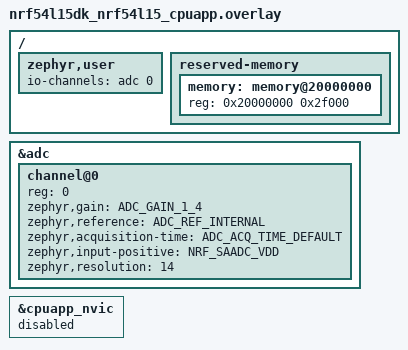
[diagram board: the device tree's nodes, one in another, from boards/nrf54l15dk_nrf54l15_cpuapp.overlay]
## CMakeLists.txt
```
#
# Copyright (c) 2020 Nordic Semiconductor ASA
#
# SPDX-License-Identifier: LicenseRef-Nordic-5-Clause
#
cmake_minimum_required(VERSION 3.20.0)

find_package(Zephyr REQUIRED HINTS $ENV{ZEPHYR_BASE})
project(chat_2)

# NORDIC SDK APP START
target_sources(app PRIVATE
	src/main.c
	src/model_handler.c
	src/chat_cli.c
	src/chat_cli_state.c
	src/chat_cli_neighbor.c
	src/chat_cli_backbone.c
	src/chat_cli_mesh.c
	src/dsdv_routing.c
	src/gradient_routing.c)
target_include_directories(app PRIVATE include)
# NORDIC SDK APP END
```

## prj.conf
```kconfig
#
# Copyright (c) 2020 Nordic Semiconductor ASA
#
# SPDX-License-Identifier: LicenseRef-Nordic-5-Clause
#
CONFIG_NCS_SAMPLES_DEFAULTS=y

# Deferred logging helps improve LPN power consumption
CONFIG_LOG_MODE_DEFERRED=y

# General configuration
CONFIG_NCS_APPLICATION_BOOT_BANNER_STRING="DSDV ROUTING NODE (50 NODES - HIGH BUFFER)"
CONFIG_SYSTEM_WORKQUEUE_STACK_SIZE=4096
CONFIG_FLASH=y
CONFIG_FLASH_MAP=y
CONFIG_NVS=y
CONFIG_SETTINGS=y
CONFIG_NVS_LOOKUP_CACHE=y
CONFIG_SETTINGS_NVS_NAME_CACHE=y
CONFIG_HWINFO=y
CONFIG_DK_LIBRARY=y
CONFIG_PM_PARTITION_SIZE_SETTINGS_STORAGE=0x8000

# Bluetooth configuration
CONFIG_BT=y
CONFIG_BT_DEVICE_NAME="DSDV NODE"
CONFIG_BT_L2CAP_TX_BUF_COUNT=64
CONFIG_BT_OBSERVER=y
CONFIG_BT_PERIPHERAL=y
CONFIG_BT_SETTINGS=y

# Disable unused Bluetooth features
CONFIG_BT_CTLR_LE_ENC=n
CONFIG_BT_PHY_UPDATE=n
CONFIG_BT_CTLR_CHAN_SEL_2=n
CONFIG_BT_CTLR_MIN_USED_CHAN=n
CONFIG_BT_CTLR_PRIVACY=n

# Bluetooth Mesh configuration
CONFIG_BT_MESH=y
# Bật Relay mặc định (để có thể tắt bằng lệnh shell sau)
CONFIG_BT_MESH_RELAY=y
CONFIG_BT_MESH_FRIEND=y 

CONFIG_BT_MESH_SEG_BUFS=128

CONFIG_BT_MESH_RX_SEG_MSG_COUNT=32

CONFIG_BT_MESH_TX_SEG_MSG_COUNT=32

CONFIG_BT_MESH_RX_SEG_MAX=32
CONFIG_BT_MESH_TX_SEG_MAX=32

CONFIG_BT_MESH_MSG_CACHE_SIZE=200

CONFIG_BT_MESH_ADV_BUF_COUNT=60

CONFIG_BT_MESH_PB_GATT=y
CONFIG_BT_MESH_GATT_PROXY=y
CONFIG_BT_MESH_DK_PROV=y

# Log Level
CONFIG_BT_MESH_LOG_LEVEL_WRN=y
CONFIG_BT_MESH_LOG_LEVEL_ERR=y
CONFIG_BT_MESH_LOG_LEVEL_INF=n
CONFIG_BT_MESH_LOG_LEVEL_DBG=n

# Shell module
CONFIG_SHELL=y
CONFIG_SHELL_BACKEND_SERIAL=y
CONFIG_FLASH_SHELL=n
CONFIG_LOG_BACKEND_RTT=n

# CONFIG_BT_CTLR_TX_PWR_MINUS_20=y
CONFIG_BT_CTLR_TX_PWR_0=y

# ADC configuration
CONFIG_ADC=y
CONFIG_ADC_NRFX_SAADC=y

CONFIG_BT_MESH_CRPL=255

CONFIG_LOG_BUFFER_SIZE=40960
```

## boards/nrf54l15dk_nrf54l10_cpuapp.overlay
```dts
/ {
	chosen {
		zephyr,console = &uart30;
		zephyr,shell-uart = &uart30;
		zephyr,uart-mcumgr = &uart30;
		zephyr,bt-mon-uart = &uart30;
		zephyr,bt-c2h-uart = &uart30;
		zephyr,flash-controller = &rram_controller;
		zephyr,flash = &cpuapp_rram;
		zephyr,ieee802154 = &ieee802154;
		zephyr,boot-mode = &boot_mode0;
	};

	aliases {
		mcuboot-button0 = &button0;
		mcuboot-led0 = &led0;
	};
};

&uart30 {
    status="okay"
	current-speed = <115200>;
	pinctrl-0 = <&uart30_default>;
	pinctrl-1 = <&uart30_sleep>;
	pinctrl-names = "default", "sleep";
};
```

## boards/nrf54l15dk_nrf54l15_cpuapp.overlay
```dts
/*
 * Copyright (c) 2025
 * SPDX-License-Identifier: LicenseRef-Nordic-5-Clause
 */

/ {
	zephyr,user {
		io-channels = <&adc 0>;
	};

	reserved-memory {
		#address-cells = <1>;
		#size-cells = <1>;
		ranges;
		memory: memory@20000000 {
			reg = <0x20000000 0x2f000>;
		};
	};
};

&adc {
	#address-cells = <1>;
	#size-cells = <0>;
	status = "okay";
	
	channel@0 {
		reg = <0>;
		zephyr,gain = "ADC_GAIN_1_4";
		zephyr,reference = "ADC_REF_INTERNAL";
		zephyr,acquisition-time = <ADC_ACQ_TIME_DEFAULT>;
		zephyr,input-positive = <NRF_SAADC_VDD>;
		zephyr,resolution = <14>;
	};
};



&cpuapp_nvic {
	status = "disabled";
};
```

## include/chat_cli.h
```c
/*
 * Copyright (c) 2020 Nordic Semiconductor ASA
 *
 * SPDX-License-Identifier: LicenseRef-Nordic-5-Clause
 */

/**
 * @file chat_cli.h
 * @defgroup bt_mesh_chat_cli Bluetooth Mesh Chat Client Model API
 * @{
 * @brief API for the Bluetooth Mesh Chat Client model with DSDV routing
 * 
 * This model implements:
 * - DSDV (Destination-Sequenced Distance-Vector) proactive routing protocol
 * - Network metrics collection (hop count, RSSI)
 * - Automatic expired route filtering (timeout-based)
 * - Remote structure querying
 */

#ifndef BT_MESH_CHAT_CLI_H__
#define BT_MESH_CHAT_CLI_H__

#include <zephyr/bluetooth/mesh.h>
#include <bluetooth/mesh/model_types.h>

#ifdef __cplusplus
extern "C" {
#endif

/* ============================================================================
 * MODEL IDENTIFICATION
 * ============================================================================ */

/** Company ID of the Bluetooth Mesh Chat Client model. */
#define BT_MESH_CHAT_CLI_VENDOR_COMPANY_ID    CONFIG_BT_COMPANY_ID_NORDIC

/** Model ID of the Bluetooth Mesh Chat Client model. */
#define BT_MESH_CHAT_CLI_VENDOR_MODEL_ID      0x000A

/* ============================================================================
 * OPCODES - Mesh message operation codes
 * ============================================================================ */

/** Opcode: Metrics acknowledgment packet */
#define BT_MESH_CHAT_CLI_OP_METRICS_ACK BT_MESH_MODEL_OP_3(0x0F, \
                                       BT_MESH_CHAT_CLI_VENDOR_COMPANY_ID)
/** Opcode: DSDV HELLO packet (neighbor discovery + RSSI) */
#define BT_MESH_CHAT_CLI_OP_DSDV_HELLO BT_MESH_MODEL_OP_3(0x12, \
									   BT_MESH_CHAT_CLI_VENDOR_COMPANY_ID)

/** Opcode: DSDV UPDATE packet (routing table exchange) */
#define BT_MESH_CHAT_CLI_OP_DSDV_UPDATE BT_MESH_MODEL_OP_3(0x13, \
									   BT_MESH_CHAT_CLI_VENDOR_COMPANY_ID)

/** Opcode: DSDV DATA packet (end-to-end data with metrics) */
#define BT_MESH_CHAT_CLI_OP_DSDV_DATA BT_MESH_MODEL_OP_3(0x14, \
									   BT_MESH_CHAT_CLI_VENDOR_COMPANY_ID)

/** Opcode: LED toggle packet (remote LED control) */
#define BT_MESH_CHAT_CLI_OP_LED_TOGGLE BT_MESH_MODEL_OP_3(0x15, \
									   BT_MESH_CHAT_CLI_VENDOR_COMPANY_ID)

/* ============================================================================
 * NODE ROLE ENUM — MCDS Backbone Selection
 * ============================================================================ */

/** Node role in the MCDS backbone hierarchy */
typedef enum {
    NODE_ROLE_UNKNOWN  = 0,  /**< Role not yet determined */
    NODE_ROLE_BACKBONE = 1,  /**< Relay ON, full routing, higher TTL */
    NODE_ROLE_LEAF     = 2,  /**< Relay OFF, local only, lower TTL */
} node_role_t;

/* ============================================================================
 * MESSAGE LENGTH CONSTANTS
 * ============================================================================ */
									   
#define BT_MESH_CHAT_CLI_MSG_LEN_DSDV_HELLO sizeof(struct dsdv_hello) /**< HELLO packet size */
#define BT_MESH_CHAT_CLI_MSG_LEN_DSDV_UPDATE_MIN 8           /**< Minimum UPDATE packet size */
#define BT_MESH_CHAT_CLI_MSG_LEN_METRICS_ACK 8               /**< Metrics ACK packet size */
#define BT_MESH_CHAT_CLI_MSG_LEN_DSDV_DATA_MAX 128           /**< Maximum DATA packet size */
#define BT_MESH_CHAT_CLI_MSG_LEN_LED_TOGGLE 8                /**< LED toggle packet size */

/* ============================================================================
 * DATA STRUCTURES - Packet formats and routing table entries
 * ============================================================================ */

/** Maximum number of neighbors to include in metrics packet */
#define MAX_NEIGHBORS_IN_METRICS 8

/**
 * @brief Network metrics packet structure
 * 
 * Contains basic network performance metrics from a node:
 * - Link quality (RSSI to target)
 * - Routing info (hop count, TTL)
 */
struct bt_mesh_network_metrics
{
	uint16_t src_addr;      /**< Source node address */
	uint16_t about_addr;    /**< Target node address (for directed metrics) */
	uint32_t timestamp;     /**< Metric collection timestamp (ms) */
	int8_t rssi_dbm;        /**< RSSI to about_addr in dBm */
	uint8_t initial_ttl;    /**< TTL used for packet transmission */
	uint8_t hop_count;      /**< Number of hops from source */
	uint8_t request_ack;    /**< 1 = request acknowledgment, 0 = no ACK needed */
	uint8_t _padding;       /**< Padding for alignment */
}__packed;

/**
 * @brief Metrics acknowledgment packet
 * 
 * Sent by destination to confirm metrics packet delivery.
 * Enables RTT (Round Trip Time) calculation.
 */
struct bt_mesh_metrics_ack{
	uint16_t src_addr;           /**< Original sender address */
	uint32_t original_timestamp; /**< Echo of original timestamp for RTT calculation */
	uint16_t padding;            /**< Padding to reach 8 bytes */
} __packed;

/**
 * @brief DSDV routing table entry
 * 
 * Stores routing information for one destination in the network.
 * Updated when receiving HELLO or UPDATE packets.
 */
struct dsdv_route_entry {
	uint16_t dest;               /**< Destination node address */
	uint16_t next_hop;           /**< Next hop node address to reach dest */
	uint8_t hop_count;           /**< Number of hops to destination (0xFF = invalidation) */
	uint32_t seq_num;            /**< Sequence number from destination (freshness / odd=invalid) */
	uint32_t last_update_time;   /**< Last successful update time (ms) */
	uint8_t changed;             
	uint8_t _pad;                /**< Padding for alignment */
}__packed;

/**
 * @brief DSDV HELLO packet structure
 * 
 * Broadcast periodically for neighbor discovery.
 * Receivers create 1-hop routes, measure RSSI, and learn neighbor degree/role
 * for MCDS backbone selection.
 */
struct dsdv_hello {
    uint16_t src;       /**< Source node address */
    uint32_t seq_num;   /**< Source's sequence number (even numbers only) */
    uint8_t  my_degree; /**< Number of active neighbors (for backbone election) */
    uint8_t  my_role;   /**< Current node role: NODE_ROLE_UNKNOWN/BACKBONE/LEAF */
    uint8_t  my_leaf_type;      /**< 0=none/backbone, 1=leaf with backbone neighbor, 2=leaf gradient-only */
    uint8_t  my_gradient_level; /**< 0 for type-1 leaf, >0 for gradient leaf, 0xFF unknown */
} __packed;

/**
 * @brief DSDV UPDATE packet header
 * 
 * Followed by num_entries route entries.
 * Shares routing table with neighbors for multi-hop routing.
 */
struct dsdv_update_header {
	uint16_t src;         /**< Source node address */
	uint8_t num_entries;  /**< Number of route entries following this header */
	uint8_t flags;        /**< Reserved flags */
} __packed;

/**
 * @brief DSDV UPDATE route entry payload
 * 
 * Sent in UPDATE packets. Does NOT include next_hop because:
 * - Receiver will set next_hop = sender_address
 * - Including next_hop would cause routing errors (transitive next_hop)
 */
struct dsdv_update_entry {
	uint16_t dest;        /**< Destination node address */
	uint8_t hop_count;    /**< Number of hops from sender to dest */
	uint32_t seq_num;     /**< Sequence number from destination */
	uint8_t padding;      /**< Padding for alignment */
} __packed;

/** Maximum number of nodes in path vector for DATA packets */
#define MAX_PATH_NODES 8

/**
 * @brief DSDV DATA packet structure
 * 
 * End-to-end data delivery with embedded metrics and path tracking.
 * Supports relay metrics collection for network analysis.
 */
struct dsdv_data_packet {
	uint16_t src;
	uint16_t dest;
	uint32_t seq_num;
	uint8_t hop_count;
	uint8_t path_len;
	uint16_t path_nodes[MAX_PATH_NODES];
	
	// Sequential mode: Only source metrics in main packet
	struct bt_mesh_network_metrics metrics;
	uint8_t collect_relay_metrics;  // Flag: 1 = relays send metrics separately
} __packed;

/**
 * @brief LED toggle message structure
 * 
 * Remote LED control message sent through DSDV routing.
 * Contains source address, destination address, and sequence number
 * for duplicate detection and routing.
 */
struct led_toggle_message {
	uint16_t src;        /**< Source node address */
	uint16_t dest;       /**< Destination node address */
	uint32_t seq_num;    /**< Sequence number for duplicate detection */
} __packed;

/* Forward declaration of the Bluetooth Mesh Chat Client model context. */
struct bt_mesh_chat_cli;

/* .. include_startingpoint_chat_cli_rst_2 */
/** @def BT_MESH_MODEL_CHAT_CLI
 *
 * @brief Bluetooth Mesh Chat Client model composition data entry.
 *
 * @param[in] _chat Pointer to a @ref bt_mesh_chat_cli instance.
 */
#define BT_MESH_MODEL_CHAT_CLI(_chat)                                          \
		BT_MESH_MODEL_VND_CB(BT_MESH_CHAT_CLI_VENDOR_COMPANY_ID,       \
			BT_MESH_CHAT_CLI_VENDOR_MODEL_ID,                      \
			_bt_mesh_chat_cli_op, &(_chat)->pub,                   \
			BT_MESH_MODEL_USER_DATA(struct bt_mesh_chat_cli,       \
						_chat),                        \
			&_bt_mesh_chat_cli_cb)
/* .. include_endpoint_chat_cli_rst_2 */

/** Bluetooth Mesh Chat Client model handlers. */
struct bt_mesh_chat_cli_handlers {
	/** @brief Called after the node has been provisioned, or after all
	 * mesh data has been loaded from persistent storage.
	 *
	 * @param[in] cli Chat Client instance that has been started.
	 */
	void (*const start)(struct bt_mesh_chat_cli *chat);

	/** @brief Handler for a network metrics message.
	 *
	 * @param[in] cli Chat client instance that received the message.
	 * @param[in] ctx Context of the incoming message.
	 * @param[in] metrics Pointer to the network metrics data.
	 */
	void (*const network_metrics)(struct bt_mesh_chat_cli *chat,
				       struct bt_mesh_msg_ctx *ctx,
				       const struct bt_mesh_network_metrics *metrics);
	
	/** @brief Handler for metrics ACK message.
	 * @param[in] chat Chat client instance.
	 * @param[in] ctx Context of the incoming message.
	 * @param[in] ack Metrics ACK data.
 */
	void (*const metrics_ack)(struct bt_mesh_chat_cli *chat,
				  struct bt_mesh_msg_ctx *ctx,
				  const struct bt_mesh_metrics_ack *ack);
};

/* .. include_startingpoint_chat_cli_rst_3 */
/**
 * Bluetooth Mesh Chat Client model context.
 */
struct bt_mesh_chat_cli {
	/** Access model pointer. */
	const struct bt_mesh_model *model;
	/** Publish parameters. */
	struct bt_mesh_model_pub pub;
	/** Publication message. */
	struct net_buf_simple pub_msg;
	/** Publication message buffer. */
	uint8_t buf[BT_MESH_MODEL_BUF_LEN(BT_MESH_CHAT_CLI_OP_DSDV_UPDATE,
					  BT_MESH_CHAT_CLI_MSG_LEN_DSDV_DATA_MAX)];
	/** Handler function structure. */
	const struct bt_mesh_chat_cli_handlers *handlers;
};
/* .. include_endpoint_chat_cli_rst_3 */

/** @brief Send network metrics to specified destination.
 *
 * @param[in] chat Chat Client model instance to send the message.
 * @param[in] addr Address of the destination node.
 * @param[in] metrics Pointer to network metrics data to send.
 *
 * @retval 0 Successfully sent the message.
 * @retval -EINVAL The model is not bound to an application key.
 * @retval -EAGAIN The device has not been provisioned.
 */
/** @brief set target node for metrics collection.
 *
 * @param[in] target_addr Address of target node for metrics.
 */
void bt_mesh_chat_cli_set_metrics_target(uint16_t target_addr);

/** @brief Get neighbor RSSI statistics.
 *
 * Returns the number of neighbors with RSSI data.
 * Fills the provided arrays with neighbor addresses and RSSI values.
 *
 * @param[out] addrs Array to store neighbor addresses (must have space for 16).
 * @param[out] rssi Array to store RSSI values (must have space for 16).
 * @param[in] max_count Maximum number of entries to return.
 *
 * @return Number of neighbors returned.
 */
int bt_mesh_chat_cli_get_neighbor_rssi(uint16_t *addrs, int8_t *rssi, int max_count);

/** @brief Send network metrics immediately via DSDV.
 *
 * Attempts to find a DSDV route and unicast a metrics packet to @p addr.
 * If no route is found, returns an error and does not publish/broadcast.
 *
 * @param[in] chat Chat Client model instance.
 * @param[in] addr Destination unicast address.
 *
 * @retval 0 on success.
 * @retval -EINVAL Invalid args or addr.
 * @retval -ENOENT No route to destination.
 */
int bt_mesh_chat_cli_metrics_send(struct bt_mesh_chat_cli *chat, uint16_t addr);


/**
 * @brief Request network structure from a node
 *
 * Sends a structure request to the specified node. The target node will
 * reply with its complete DSDV routing table, showing all known nodes,
 * their next_hop addresses, hop counts, and RSSI values.
 *
 * @param[in] chat Chat Client model instance.
 * @param[in] dest Destination unicast address to request structure from.
 *
 * @retval 0 on success.
 * @retval -EINVAL Invalid arguments or destination address.
 * @retval -ENOENT No route to destination.
 */
int bt_mesh_chat_cli_structure_request(struct bt_mesh_chat_cli *chat, uint16_t dest);

/**
 * @brief Send LED toggle command to a remote node
 *
 * Sends an LED toggle message to the specified destination node through
 * DSDV routing. The target node will blink its LED1 three times upon
 * receiving the message.
 *
 * @param[in] chat Chat Client model instance.
 * @param[in] dest Destination unicast address to send LED toggle command.
 *
 * @retval 0 on success.
 * @retval -EINVAL Invalid arguments or destination address.
 * @retval -ENOENT No route to destination.
 */
int bt_mesh_chat_cli_led_toggle_send(struct bt_mesh_chat_cli *chat, uint16_t dest);

/** @brief Get the current node role (BACKBONE/LEAF/UNKNOWN).
 * @return Current node_role_t value.
 */
node_role_t bt_mesh_chat_cli_get_node_role(void);

/** @brief Get list of known backbone node addresses.
 * @param[out] backbone_addrs Array to fill with backbone addresses.
 * @param[in] max_count Maximum entries to return.
 * @return Number of backbone nodes found.
 */
int bt_mesh_chat_cli_get_backbone_info(uint16_t *backbone_addrs, int max_count);

/** @brief Get the current node's backbone score.
 * @return Centrality score used in backbone election.
 */
uint16_t bt_mesh_chat_cli_get_backbone_score(void);

/** @cond INTERNAL_HIDDEN */
extern const struct bt_mesh_model_op _bt_mesh_chat_cli_op[];
extern const struct bt_mesh_model_cb _bt_mesh_chat_cli_cb;
/** @endcond */

#ifdef __cplusplus
}
#endif

#endif /* BT_MESH_CHAT_CLI_H__ */

/** @} */
```

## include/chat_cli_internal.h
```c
/*
 * Shared state and internal API for Bluetooth Mesh Chat Client (DSDV + backbone + hybrid).
 */

#ifndef CHAT_CLI_INTERNAL_H__
#define CHAT_CLI_INTERNAL_H__

#include <stddef.h>
#include <stdint.h>

#include <zephyr/bluetooth/mesh.h>
#include <zephyr/kernel.h>

#include "chat_cli.h"
#include "dsdv_routing.h"
#include "gradient_routing.h"

#ifdef __cplusplus
extern "C" {
#endif

#define MAX_UPDATE_ENTRIES 12
#define MAX_RSSI_NEIGHBORS 32
#define NEIGHBOR_RSSI_VALID_WINDOW_MS 90000
#define MAX_ROUTE_HISTORY 5
#define UPDATE_MIN_INTERVAL_MS 3000

#define TTL_HELLO 1
#define TTL_DEFAULT_MAX 10

#define BACKBONE_RSSI_THRESHOLD (-70)
#define BACKBONE_RSSI_REJECT (-80)
#define BACKBONE_MIN_DEGREE 3
#define BACKBONE_PROMOTE_MIN_DEGREE 2
#define BACKBONE_PROMOTE_RSSI (-80)
#define BACKBONE_EVAL_INTERVAL_MS 30000
#define BACKBONE_INITIAL_DELAY_MS 15000
#define BACKBONE_PDR_REJECT 50
#define BACKBONE_PDR_WINDOW_MS 60000
#define BACKBONE_EXPECTED_HELLO_MS 12000

typedef enum {
	CHAT_CLI_MSG_HELLO,
	CHAT_CLI_MSG_UPDATE,
	CHAT_CLI_MSG_UNICAST_DATA,
	CHAT_CLI_MSG_BROADCAST_APP,
} chat_cli_msg_type_t;

typedef struct {
	uint16_t addr;
	int8_t rssi;
	uint32_t last_update;
} chat_cli_neighbor_rssi_t;

typedef struct {
	uint16_t addr;
	uint8_t degree;
	uint8_t role;
	uint8_t leaf_type;
	uint8_t gradient_level;
	int8_t avg_rssi;
	uint32_t last_seen;
	uint16_t hello_rx_count;
	uint32_t pdr_window_start;
} chat_cli_backbone_peer_t;

extern struct bt_mesh_chat_cli *g_chat_cli_instance;
extern struct k_work_delayable dsdv_hello_work;
extern struct k_work_delayable dsdv_update_work;
extern struct k_work_delayable print_routes_work;
extern struct k_work_delayable backbone_selection_work;

extern chat_cli_neighbor_rssi_t neighbor_rssi[MAX_RSSI_NEIGHBORS];
extern chat_cli_backbone_peer_t neighbor_backbone_info[MAX_RSSI_NEIGHBORS];

extern node_role_t g_my_role;
extern uint16_t g_my_degree;
extern uint16_t g_my_backbone_score;
extern struct gradient_state g_gradient_state;

extern uint16_t current_target_node;
extern uint32_t g_dsdv_my_seq;
extern uint32_t last_update_sent_time;

typedef struct {
	uint32_t packets_sent;
	uint32_t packets_acked;
	uint32_t window_start;
} chat_cli_delivery_stats_t;

extern chat_cli_delivery_stats_t delivery_stats;

/* neighbor_rssi.c */
void chat_cli_update_neighbor_rssi(uint16_t addr, int8_t rssi);
int8_t chat_cli_get_neighbor_rssi(uint16_t addr);
int8_t chat_cli_dsdv_rssi_cb(uint16_t addr);

/* backbone.c */
void chat_cli_backbone_evaluate(void);
void chat_cli_backbone_selection_handler(struct k_work *work);
void chat_cli_refresh_leaf_routing_mode(void);
uint16_t chat_cli_select_hybrid_next_hop(uint16_t dest);

/* mesh_handlers.c */
uint8_t chat_cli_calc_ttl(chat_cli_msg_type_t type, uint16_t dst);
void chat_cli_dsdv_send_hello(struct k_work *work);
void chat_cli_dsdv_send_update(struct k_work *work);
void chat_cli_print_routes_handler(struct k_work *work);
void chat_cli_print_routing_table(void);
void chat_cli_check_delivery_window(void);

int chat_cli_handle_dsdv_hello(const struct bt_mesh_model *model, struct bt_mesh_msg_ctx *ctx,
			       struct net_buf_simple *buf);
int chat_cli_handle_dsdv_update(const struct bt_mesh_model *model, struct bt_mesh_msg_ctx *ctx,
				struct net_buf_simple *buf);
int chat_cli_handle_dsdv_data(const struct bt_mesh_model *model, struct bt_mesh_msg_ctx *ctx,
			      struct net_buf_simple *buf);
int chat_cli_handle_led_toggle(const struct bt_mesh_model *model, struct bt_mesh_msg_ctx *ctx,
			       struct net_buf_simple *buf);
int chat_cli_handle_metrics_ack(const struct bt_mesh_model *model, struct bt_mesh_msg_ctx *ctx,
				struct net_buf_simple *buf);

void chat_cli_collect_current_metrics(struct bt_mesh_chat_cli *chat,
				      struct bt_mesh_network_metrics *metrics);
void chat_cli_send_metrics_ack(struct bt_mesh_chat_cli *chat, struct bt_mesh_msg_ctx *ctx,
			       const struct bt_mesh_network_metrics *original_metrics);

#ifdef __cplusplus
}
#endif

#endif /* CHAT_CLI_INTERNAL_H__ */
```

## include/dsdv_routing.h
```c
/*
 * DSDV (Destination-Sequenced Distance-Vector) routing core for mesh chat.
 */

#ifndef DSDV_ROUTING_H__
#define DSDV_ROUTING_H__

#include <stdbool.h>
#include <stdint.h>

#include "chat_cli.h"

#ifdef __cplusplus
extern "C" {
#endif

#define DSDV_ROUTE_TABLE_SIZE 64
#define DSDV_DUP_CACHE_SIZE 100

#define DSDV_NEIGHBOR_TIMEOUT_MS 45000
#define DSDV_ROUTE_TIMEOUT_MS    120000
#define ROUTE_SETTLE_TIME_MS     10000

extern struct dsdv_route_entry g_dsdv_routes[DSDV_ROUTE_TABLE_SIZE];

extern bool dsdv_route_changed;
extern bool dsdv_my_info_changed;

typedef int8_t (*dsdv_get_neighbor_rssi_fn)(uint16_t addr);

struct dsdv_route_entry *dsdv_find_route(uint16_t dest);

void dsdv_cleanup_expired_routes(void);

bool dsdv_upsert(uint16_t dest, uint16_t next_hop, uint8_t hop_count, uint32_t seq_num,
		 dsdv_get_neighbor_rssi_fn get_rssi);

bool dsdv_seen_duplicate(uint16_t src, uint32_t seq);

#ifdef __cplusplus
}
#endif

#endif /* DSDV_ROUTING_H__ */
```

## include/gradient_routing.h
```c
#ifndef GRADIENT_ROUTING_H__
#define GRADIENT_ROUTING_H__

#include <stddef.h>
#include <stdint.h>

#include "chat_cli.h"

#ifdef __cplusplus
extern "C" {
#endif

#define LEAF_TYPE_NONE 0
#define LEAF_TYPE_BACKBONE_NEIGHBOR 1
#define LEAF_TYPE_GRADIENT 2
#define GRADIENT_LEVEL_UNKNOWN 0xFF

struct gradient_neighbor_info {
    uint16_t addr;
    uint8_t role;
    uint8_t leaf_type;
    uint8_t gradient_level;
    int8_t rssi;
    uint32_t last_seen;
};

struct gradient_state {
    uint8_t leaf_type;
    uint8_t gradient_level;
    uint16_t attached_backbone;
    uint16_t gradient_next_hop;
};

void gradient_compute_state(node_role_t my_role,
                            const struct gradient_neighbor_info *neighbors,
                            size_t neighbor_count,
                            uint32_t now_ms,
                            uint32_t valid_window_ms,
                            struct gradient_state *state);

uint16_t gradient_pick_next_hop(uint16_t dsdv_next_hop,
                                node_role_t my_role,
                                const struct gradient_state *state);

#ifdef __cplusplus
}
#endif

#endif /* GRADIENT_ROUTING_H__ */
```

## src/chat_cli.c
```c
/*
 * Copyright (c) 2019 Nordic Semiconductor ASA
 *
 * SPDX-License-Identifier: LicenseRef-Nordic-5-Clause
 */

/**
 * @file chat_cli.c
 * @brief Bluetooth Mesh Chat Client model: registration, lifecycle, opcode table.
 */

#include <zephyr/bluetooth/mesh.h>

#include "chat_cli.h"
#include "chat_cli_internal.h"

#include <zephyr/kernel.h>
#include <zephyr/random/random.h>

#ifdef CONFIG_BT_SETTINGS
#include <zephyr/settings/settings.h>
#endif

const struct bt_mesh_model_op _bt_mesh_chat_cli_op[] = {
	{ BT_MESH_CHAT_CLI_OP_METRICS_ACK, BT_MESH_LEN_EXACT(BT_MESH_CHAT_CLI_MSG_LEN_METRICS_ACK),
	  chat_cli_handle_metrics_ack },
	{ BT_MESH_CHAT_CLI_OP_DSDV_HELLO, BT_MESH_LEN_EXACT(sizeof(struct dsdv_hello)),
	  chat_cli_handle_dsdv_hello },
	{ BT_MESH_CHAT_CLI_OP_DSDV_UPDATE, BT_MESH_LEN_MIN(BT_MESH_CHAT_CLI_MSG_LEN_DSDV_UPDATE_MIN),
	  chat_cli_handle_dsdv_update },
	{ BT_MESH_CHAT_CLI_OP_DSDV_DATA, BT_MESH_LEN_MIN(sizeof(struct dsdv_data_packet)),
	  chat_cli_handle_dsdv_data },
	{ BT_MESH_CHAT_CLI_OP_LED_TOGGLE, BT_MESH_LEN_EXACT(BT_MESH_CHAT_CLI_MSG_LEN_LED_TOGGLE),
	  chat_cli_handle_led_toggle },
	BT_MESH_MODEL_OP_END,
};

#ifdef CONFIG_BT_SETTINGS
static int bt_mesh_chat_cli_settings_set(const struct bt_mesh_model *model, const char *name,
					   size_t len_rd, settings_read_cb read_cb, void *cb_arg)
{
	if (name) {
		return -ENOENT;
	}
	return 0;
}
#endif

static int bt_mesh_chat_cli_init(const struct bt_mesh_model *model)
{
	struct bt_mesh_chat_cli *chat = model->rt->user_data;

	chat->model = model;
	net_buf_simple_init_with_data(&chat->pub_msg, chat->buf, sizeof(chat->buf));
	chat->pub.msg = &chat->pub_msg;
	chat->pub.update = NULL;
	k_work_init_delayable(&dsdv_hello_work, chat_cli_dsdv_send_hello);
	k_work_init_delayable(&dsdv_update_work, chat_cli_dsdv_send_update);
	k_work_init_delayable(&print_routes_work, chat_cli_print_routes_handler);
	k_work_init_delayable(&backbone_selection_work, chat_cli_backbone_selection_handler);
	return 0;
}

static int bt_mesh_chat_cli_start(const struct bt_mesh_model *model)
{
	struct bt_mesh_chat_cli *chat = model->rt->user_data;

	if (chat->handlers->start) {
		chat->handlers->start(chat);
	}
	g_chat_cli_instance = chat;

	k_work_schedule(&dsdv_hello_work, K_MSEC(2000 + (sys_rand32_get() % 5000)));
	k_work_schedule(&dsdv_update_work, K_MSEC(3000 + (sys_rand32_get() % 2000)));
	k_work_schedule(&print_routes_work, K_MSEC(10000));
	k_work_schedule(&backbone_selection_work,
			K_MSEC(BACKBONE_INITIAL_DELAY_MS + (sys_rand32_get() % 5000)));
	return 0;
}

const struct bt_mesh_model_cb _bt_mesh_chat_cli_cb = {
	.init = bt_mesh_chat_cli_init,
	.start = bt_mesh_chat_cli_start,
#ifdef CONFIG_BT_SETTINGS
	.settings_set = bt_mesh_chat_cli_settings_set,
#endif
};

void bt_mesh_chat_cli_set_metrics_target(uint16_t target_addr)
{
	current_target_node = target_addr;
}
```

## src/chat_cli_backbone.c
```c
/*
 * MCDS backbone election + hybrid gradient next-hop.
 */

#include "chat_cli_internal.h"

#include <zephyr/logging/log.h>
#include <zephyr/random/random.h>

LOG_MODULE_DECLARE(chat);

static int8_t calc_avg_neighbor_rssi(void)
{
	int32_t sum = 0;
	int count = 0;
	uint32_t now = k_uptime_get_32();

	for (int i = 0; i < MAX_RSSI_NEIGHBORS; i++) {
		if (neighbor_rssi[i].addr != 0 &&
		    (now - neighbor_rssi[i].last_update) < NEIGHBOR_RSSI_VALID_WINDOW_MS) {
			sum += neighbor_rssi[i].rssi;
			count++;
		}
	}
	return (count > 0) ? (int8_t)(sum / count) : -127;
}

static uint8_t calc_avg_neighbor_pdr(void)
{
	uint32_t now = k_uptime_get_32();
	uint32_t total_pdr = 0;
	int count = 0;

	for (int i = 0; i < MAX_RSSI_NEIGHBORS; i++) {
		if (neighbor_backbone_info[i].addr == 0) {
			continue;
		}
		if ((now - neighbor_backbone_info[i].last_seen) > NEIGHBOR_RSSI_VALID_WINDOW_MS) {
			continue;
		}

		uint32_t window_ms = now - neighbor_backbone_info[i].pdr_window_start;
		if (window_ms < 5000) {
			total_pdr += 100;
			count++;
			continue;
		}

		uint16_t expected = (uint16_t)(window_ms / BACKBONE_EXPECTED_HELLO_MS);
		if (expected == 0) {
			expected = 1;
		}

		uint16_t pdr = (neighbor_backbone_info[i].hello_rx_count * 100) / expected;
		if (pdr > 100) {
			pdr = 100;
		}

		total_pdr += pdr;
		count++;
	}

	return (count > 0) ? (uint8_t)(total_pdr / count) : 0;
}

static uint16_t calc_backbone_score_for(uint8_t degree, int8_t avg_rssi, uint8_t pdr)
{
	int16_t rssi_score = (int16_t)(avg_rssi + 100);
	if (rssi_score < 0) {
		rssi_score = 0;
	}
	if (rssi_score > 70) {
		rssi_score = 70;
	}
	uint16_t pdr_bonus = (uint16_t)(pdr * 30 / 100);
	return (uint16_t)(degree * 100) + (uint16_t)rssi_score + pdr_bonus;
}

void chat_cli_backbone_evaluate(void)
{
	if (!g_chat_cli_instance || !g_chat_cli_instance->model) {
		return;
	}

	uint16_t my_addr = bt_mesh_model_elem(g_chat_cli_instance->model)->rt->addr;
	uint32_t now = k_uptime_get_32();
	node_role_t old_role = g_my_role;

	uint16_t active_neighbors = 0;
	for (int i = 0; i < MAX_RSSI_NEIGHBORS; i++) {
		if (neighbor_rssi[i].addr != 0 &&
		    (now - neighbor_rssi[i].last_update) < NEIGHBOR_RSSI_VALID_WINDOW_MS) {
			active_neighbors++;
		}
	}
	g_my_degree = active_neighbors;

	int8_t my_avg_rssi = calc_avg_neighbor_rssi();
	uint8_t my_avg_pdr = calc_avg_neighbor_pdr();

	if (g_my_degree < 2) {
		g_my_role = NODE_ROLE_LEAF;
		g_my_backbone_score = 0;
		LOG_INF("BACKBONE: LEAF (degree %u < 2, edge node)", g_my_degree);
		goto apply_role;
	}

	if (my_avg_rssi < BACKBONE_RSSI_REJECT) {
		g_my_role = NODE_ROLE_LEAF;
		g_my_backbone_score = 0;
		LOG_INF("BACKBONE: LEAF (avg RSSI %d < %d, weak signal)", my_avg_rssi,
			BACKBONE_RSSI_REJECT);
		goto apply_role;
	}

	if (my_avg_pdr < BACKBONE_PDR_REJECT) {
		g_my_role = NODE_ROLE_LEAF;
		g_my_backbone_score = 0;
		LOG_INF("BACKBONE: LEAF (avg PDR %u%% < %d%%, unreliable)", my_avg_pdr,
			BACKBONE_PDR_REJECT);
		goto apply_role;
	}

	uint16_t my_score = calc_backbone_score_for((uint8_t)g_my_degree, my_avg_rssi, my_avg_pdr);
	g_my_backbone_score = my_score;

	bool i_am_highest = true;

	for (int i = 0; i < MAX_RSSI_NEIGHBORS; i++) {
		if (neighbor_backbone_info[i].addr == 0) {
			continue;
		}
		if ((now - neighbor_backbone_info[i].last_seen) > NEIGHBOR_RSSI_VALID_WINDOW_MS) {
			continue;
		}

		uint8_t nb_pdr = 100;
		{
			uint32_t w = now - neighbor_backbone_info[i].pdr_window_start;
			if (w > 5000) {
				uint16_t exp = (uint16_t)(w / BACKBONE_EXPECTED_HELLO_MS);
				if (exp == 0) {
					exp = 1;
				}
				nb_pdr = (uint8_t)((neighbor_backbone_info[i].hello_rx_count * 100) / exp);
				if (nb_pdr > 100) {
					nb_pdr = 100;
				}
			}
		}
		uint16_t neighbor_score = calc_backbone_score_for(neighbor_backbone_info[i].degree,
								  neighbor_backbone_info[i].avg_rssi,
								  nb_pdr);

		if (neighbor_score > my_score) {
			i_am_highest = false;
			break;
		} else if (neighbor_score == my_score) {
			if (neighbor_backbone_info[i].addr < my_addr) {
				i_am_highest = false;
				break;
			}
		}
	}

	if (i_am_highest && g_my_degree >= BACKBONE_MIN_DEGREE && my_avg_rssi >= BACKBONE_RSSI_THRESHOLD &&
	    my_avg_pdr >= BACKBONE_PDR_REJECT) {
		g_my_role = NODE_ROLE_BACKBONE;
	} else {
		g_my_role = NODE_ROLE_LEAF;
	}

	if (g_my_role == NODE_ROLE_LEAF) {
		bool has_backbone_neighbor = false;

		for (int i = 0; i < MAX_RSSI_NEIGHBORS; i++) {
			if (neighbor_backbone_info[i].addr == 0) {
				continue;
			}
			if ((now - neighbor_backbone_info[i].last_seen) > NEIGHBOR_RSSI_VALID_WINDOW_MS) {
				continue;
			}

			if (neighbor_backbone_info[i].role == NODE_ROLE_BACKBONE) {
				has_backbone_neighbor = true;
				break;
			}
		}

		if (!has_backbone_neighbor && g_my_degree >= BACKBONE_PROMOTE_MIN_DEGREE &&
		    my_avg_rssi >= BACKBONE_PROMOTE_RSSI && my_avg_pdr >= BACKBONE_PDR_REJECT) {
			g_my_role = NODE_ROLE_BACKBONE;
			LOG_INF("BACKBONE: Forced BACKBONE (isolated, promote thresholds met)");
		}
	}

	LOG_INF("BACKBONE: Role=%s Score=%u Degree=%u AvgRSSI=%d",
		(g_my_role == NODE_ROLE_BACKBONE) ? "BACKBONE" : "LEAF", g_my_backbone_score, g_my_degree,
		my_avg_rssi);

apply_role:
	if (g_my_role != old_role) {
#if defined(CONFIG_BT_MESH_CFG_SRV)
		extern void bt_mesh_cfg_srv_relay_set(uint8_t new_relay, uint8_t new_transmit);
		if (g_my_role == NODE_ROLE_BACKBONE) {
			bt_mesh_cfg_srv_relay_set(BT_MESH_RELAY_ENABLED, BT_MESH_TRANSMIT(2, 20));
			LOG_INF("BACKBONE: Relay ENABLED (Backbone node)");
		} else {
			bt_mesh_cfg_srv_relay_set(BT_MESH_RELAY_DISABLED, BT_MESH_TRANSMIT(2, 20));
			LOG_INF("BACKBONE: Relay DISABLED (Leaf node)");
		}
#endif
	}
	chat_cli_refresh_leaf_routing_mode();
}

void chat_cli_refresh_leaf_routing_mode(void)
{
	uint32_t now = k_uptime_get_32();
	struct gradient_neighbor_info grad_neighbors[MAX_RSSI_NEIGHBORS];
	size_t grad_count = 0;

	for (int i = 0; i < MAX_RSSI_NEIGHBORS; i++) {
		if (neighbor_backbone_info[i].addr == 0) {
			continue;
		}
		grad_neighbors[grad_count].addr = neighbor_backbone_info[i].addr;
		grad_neighbors[grad_count].role = neighbor_backbone_info[i].role;
		grad_neighbors[grad_count].leaf_type = neighbor_backbone_info[i].leaf_type;
		grad_neighbors[grad_count].gradient_level = neighbor_backbone_info[i].gradient_level;
		grad_neighbors[grad_count].rssi = chat_cli_get_neighbor_rssi(neighbor_backbone_info[i].addr);
		grad_neighbors[grad_count].last_seen = neighbor_backbone_info[i].last_seen;
		grad_count++;
	}

	gradient_compute_state(g_my_role, grad_neighbors, grad_count, now, NEIGHBOR_RSSI_VALID_WINDOW_MS,
			       &g_gradient_state);

	if (g_gradient_state.leaf_type == LEAF_TYPE_GRADIENT && g_gradient_state.gradient_next_hop == 0) {
		g_gradient_state.gradient_level = GRADIENT_LEVEL_UNKNOWN;
	}
}

uint16_t chat_cli_select_hybrid_next_hop(uint16_t dest)
{
	struct dsdv_route_entry *route = dsdv_find_route(dest);
	uint16_t dsdv_next = (route != NULL) ? route->next_hop : 0;
	return gradient_pick_next_hop(dsdv_next, g_my_role, &g_gradient_state);
}

void chat_cli_backbone_selection_handler(struct k_work *work)
{
	chat_cli_backbone_evaluate();
	k_work_reschedule(&backbone_selection_work,
			  K_MSEC(BACKBONE_EVAL_INTERVAL_MS + (sys_rand32_get() % 5000)));
}

node_role_t bt_mesh_chat_cli_get_node_role(void)
{
	return g_my_role;
}

uint16_t bt_mesh_chat_cli_get_backbone_score(void)
{
	return g_my_backbone_score;
}

int bt_mesh_chat_cli_get_backbone_info(uint16_t *backbone_addrs, int max_count)
{
	int count = 0;
	uint32_t now = k_uptime_get_32();

	for (int i = 0; i < MAX_RSSI_NEIGHBORS && count < max_count; i++) {
		if (neighbor_backbone_info[i].addr != 0 &&
		    neighbor_backbone_info[i].role == NODE_ROLE_BACKBONE &&
		    (now - neighbor_backbone_info[i].last_seen) < NEIGHBOR_RSSI_VALID_WINDOW_MS) {
			backbone_addrs[count++] = neighbor_backbone_info[i].addr;
		}
	}
	return count;
}
```

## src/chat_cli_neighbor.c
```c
/*
 * Per-neighbor RSSI EWMA and DSDV upsert RSSI callback.
 */

#include "chat_cli_internal.h"

static inline int8_t rssi_ewma(int8_t prev, int8_t now)
{
	int32_t acc = (31 * (int32_t)prev + (int32_t)now) / 32;
	if (acc > 127) {
		acc = 127;
	}
	if (acc < -128) {
		acc = -128;
	}
	return (int8_t)acc;
}

void chat_cli_update_neighbor_rssi(uint16_t addr, int8_t rssi)
{
	uint32_t now = k_uptime_get_32();
	int8_t old_rssi = rssi;
	int oldest_idx = 0;
	uint32_t oldest_time = neighbor_rssi[0].last_update;

	for (int i = 0; i < MAX_RSSI_NEIGHBORS; i++) {
		if (neighbor_rssi[i].addr == addr) {
			old_rssi = neighbor_rssi[i].rssi;
			neighbor_rssi[i].rssi = rssi_ewma(old_rssi, rssi);
			neighbor_rssi[i].last_update = now;
			return;
		}
		if (neighbor_rssi[i].last_update < oldest_time) {
			oldest_idx = i;
			oldest_time = neighbor_rssi[i].last_update;
		}
	}
	neighbor_rssi[oldest_idx].addr = addr;
	neighbor_rssi[oldest_idx].rssi = rssi;
	neighbor_rssi[oldest_idx].last_update = now;
}

int8_t chat_cli_get_neighbor_rssi(uint16_t addr)
{
	for (int i = 0; i < MAX_RSSI_NEIGHBORS; i++) {
		if (neighbor_rssi[i].addr == addr) {
			return neighbor_rssi[i].rssi;
		}
	}
	return -127;
}

int8_t chat_cli_dsdv_rssi_cb(uint16_t addr)
{
	return chat_cli_get_neighbor_rssi(addr);
}

int bt_mesh_chat_cli_get_neighbor_rssi(uint16_t *addrs, int8_t *rssi, int max_count)
{
	int count = 0;
	uint32_t now = k_uptime_get_32();

	for (int i = 0; i < MAX_RSSI_NEIGHBORS && count < max_count; i++) {
		if (neighbor_rssi[i].addr != 0 &&
		    (now - neighbor_rssi[i].last_update) < NEIGHBOR_RSSI_VALID_WINDOW_MS) {
			addrs[count] = neighbor_rssi[i].addr;
			rssi[count] = neighbor_rssi[i].rssi;
			count++;
		}
	}
	return count;
}
```

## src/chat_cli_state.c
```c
/*
 * Global state for Mesh Chat Client (single TU for linkage).
 */

#include "chat_cli_internal.h"

struct bt_mesh_chat_cli *g_chat_cli_instance;

struct k_work_delayable dsdv_hello_work;
struct k_work_delayable dsdv_update_work;
struct k_work_delayable print_routes_work;
struct k_work_delayable backbone_selection_work;

chat_cli_neighbor_rssi_t neighbor_rssi[MAX_RSSI_NEIGHBORS];
chat_cli_backbone_peer_t neighbor_backbone_info[MAX_RSSI_NEIGHBORS];

node_role_t g_my_role = NODE_ROLE_UNKNOWN;
uint16_t g_my_degree;
uint16_t g_my_backbone_score;
struct gradient_state g_gradient_state = {
	.leaf_type = LEAF_TYPE_NONE,
	.gradient_level = GRADIENT_LEVEL_UNKNOWN,
	.attached_backbone = 0,
	.gradient_next_hop = 0,
};

uint16_t current_target_node;
uint32_t g_dsdv_my_seq;
uint32_t last_update_sent_time;

chat_cli_delivery_stats_t delivery_stats = {0};
```

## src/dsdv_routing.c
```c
/*
 * DSDV routing table: find, expire, upsert, duplicate detection.
 */

#include "dsdv_routing.h"

#include <stdint.h>
#include <string.h>
#include <zephyr/kernel.h>

struct dsdv_route_entry g_dsdv_routes[DSDV_ROUTE_TABLE_SIZE];

bool dsdv_route_changed;
bool dsdv_my_info_changed;

struct dsdv_dup_cache {
	uint16_t src;
	uint32_t last_seq;
};

static struct dsdv_dup_cache g_dup_cache[DSDV_DUP_CACHE_SIZE];

struct dsdv_route_entry *dsdv_find_route(uint16_t dest)
{
	uint32_t now = k_uptime_get_32();

	for (int i = 0; i < DSDV_ROUTE_TABLE_SIZE; ++i) {
		if (g_dsdv_routes[i].dest == dest) {
			struct dsdv_route_entry *e = &g_dsdv_routes[i];
			bool is_direct_neighbor = (e->dest == e->next_hop && e->hop_count == 1);
			uint32_t timeout = is_direct_neighbor ? DSDV_NEIGHBOR_TIMEOUT_MS
							      : DSDV_ROUTE_TIMEOUT_MS;
			if ((now - e->last_update_time) > timeout) {
				return NULL;
			}
			return e;
		}
	}
	return NULL;
}

void dsdv_cleanup_expired_routes(void)
{
	uint32_t now = k_uptime_get_32();

	for (int i = 0; i < DSDV_ROUTE_TABLE_SIZE; ++i) {
		if (g_dsdv_routes[i].dest != 0) {
			uint32_t age_ms = now - g_dsdv_routes[i].last_update_time;
			bool is_direct_neighbor =
				(g_dsdv_routes[i].dest == g_dsdv_routes[i].next_hop &&
				 g_dsdv_routes[i].hop_count == 1);
			uint32_t timeout = is_direct_neighbor ? DSDV_NEIGHBOR_TIMEOUT_MS
							      : DSDV_ROUTE_TIMEOUT_MS;

			if (age_ms > timeout) {
				if (g_dsdv_routes[i].hop_count != 0xFF) {
					uint16_t broken = g_dsdv_routes[i].dest;
					g_dsdv_routes[i].hop_count = 0xFF;
					if ((g_dsdv_routes[i].seq_num & 1) == 0) {
						g_dsdv_routes[i].seq_num += 1;
					}
					g_dsdv_routes[i].changed = 1;
					dsdv_route_changed = true;
					g_dsdv_routes[i].last_update_time = now;
					if (is_direct_neighbor) {
						dsdv_my_info_changed = true;
					}
					for (int j = 0; j < DSDV_ROUTE_TABLE_SIZE; ++j) {
						if (g_dsdv_routes[j].dest != 0 &&
						    g_dsdv_routes[j].next_hop == broken &&
						    g_dsdv_routes[j].hop_count != 0xFF) {
							g_dsdv_routes[j].hop_count = 0xFF;
							g_dsdv_routes[j].last_update_time = now;
							g_dsdv_routes[j].changed = 1;
							dsdv_route_changed = true;
						}
					}
				} else {
					g_dsdv_routes[i].dest = 0;
					g_dsdv_routes[i].next_hop = 0;
					g_dsdv_routes[i].hop_count = 0;
					g_dsdv_routes[i].seq_num = 0;
					g_dsdv_routes[i].last_update_time = 0;
				}
			}
		}
	}
}

bool dsdv_upsert(uint16_t dest, uint16_t next_hop, uint8_t hop_count, uint32_t seq_num,
		 dsdv_get_neighbor_rssi_fn get_rssi)
{
	uint32_t now = k_uptime_get_32();
	bool local_changed = false;
	bool is_direct_neighbor_new = (dest == next_hop && hop_count == 1);

	struct dsdv_route_entry *e = NULL;

	for (int i = 0; i < DSDV_ROUTE_TABLE_SIZE; ++i) {
		if (g_dsdv_routes[i].dest == dest) {
			e = &g_dsdv_routes[i];
			break;
		}
	}

	if (e != NULL) {
		uint32_t age = now - e->last_update_time;
		bool is_direct_neighbor = (e->dest == e->next_hop && e->hop_count == 1);
		uint32_t timeout = is_direct_neighbor ? DSDV_NEIGHBOR_TIMEOUT_MS
							: DSDV_ROUTE_TIMEOUT_MS;

		if (age > timeout) {
			*e = (struct dsdv_route_entry){
				.dest = dest,
				.next_hop = next_hop,
				.hop_count = hop_count,
				.seq_num = seq_num,
				.last_update_time = now,
				.changed = 1,
			};
			if (is_direct_neighbor_new) {
				dsdv_my_info_changed = true;
			}
			dsdv_route_changed = true;
			local_changed = true;
			return local_changed;
		}

		if (seq_num > e->seq_num) {
			e->next_hop = next_hop;
			e->hop_count = hop_count;
			e->seq_num = seq_num;
			e->last_update_time = now;
			e->changed = 1;
			dsdv_route_changed = true;
			local_changed = true;
			if (is_direct_neighbor_new) {
				dsdv_my_info_changed = true;
			}
			return local_changed;
		} else if (seq_num == e->seq_num) {
			if (hop_count < e->hop_count) {
				uint32_t route_age = now - e->last_update_time;
				if (route_age > ROUTE_SETTLE_TIME_MS || (e->hop_count - hop_count) >= 2) {
					e->next_hop = next_hop;
					e->hop_count = hop_count;
					e->seq_num = seq_num;
					e->last_update_time = now;
					e->changed = 1;
					dsdv_route_changed = true;
					local_changed = true;
				} else {
					e->last_update_time = now;
				}
			} else if (hop_count == e->hop_count && get_rssi != NULL) {
				int8_t new_rssi = get_rssi(next_hop);
				int8_t old_rssi = get_rssi(e->next_hop);
				uint32_t route_age = now - e->last_update_time;
				if (new_rssi != -127 && old_rssi != -127 &&
				    new_rssi >= old_rssi + 10 &&
				    route_age > ROUTE_SETTLE_TIME_MS) {
					e->next_hop = next_hop;
					e->hop_count = hop_count;
					e->last_update_time = now;
					e->changed = 1;
					dsdv_route_changed = true;
					local_changed = true;
				} else {
					e->last_update_time = now;
				}
			}
		}
	} else {
		int slot = -1;
		uint32_t oldest_time = UINT32_MAX;

		for (int i = 0; i < DSDV_ROUTE_TABLE_SIZE; ++i) {
			if (g_dsdv_routes[i].dest == 0) {
				slot = i;
				break;
			}
			if (g_dsdv_routes[i].last_update_time < oldest_time) {
				oldest_time = g_dsdv_routes[i].last_update_time;
				slot = i;
			}
		}

		g_dsdv_routes[slot] = (struct dsdv_route_entry){
			.dest = dest,
			.next_hop = next_hop,
			.hop_count = hop_count,
			.seq_num = seq_num,
			.last_update_time = now,
			.changed = 1,
		};
		dsdv_route_changed = true;
		local_changed = true;
		if (is_direct_neighbor_new) {
			dsdv_my_info_changed = true;
		}
	}

	return local_changed;
}

bool dsdv_seen_duplicate(uint16_t src, uint32_t seq)
{
	for (int i = 0; i < DSDV_DUP_CACHE_SIZE; ++i) {
		if (g_dup_cache[i].src == src) {
			if (seq <= g_dup_cache[i].last_seq) {
				return true;
			}
			g_dup_cache[i].last_seq = seq;
			return false;
		}
	}
	for (int i = 0; i < DSDV_DUP_CACHE_SIZE; ++i) {
		if (g_dup_cache[i].src == 0) {
			g_dup_cache[i].src = src;
			g_dup_cache[i].last_seq = seq;
			return false;
		}
	}
	g_dup_cache[0].src = src;
	g_dup_cache[0].last_seq = seq;
	return false;
}
```

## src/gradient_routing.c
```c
#include "gradient_routing.h"
#include <stdbool.h>

void gradient_compute_state(node_role_t my_role,
                            const struct gradient_neighbor_info *neighbors,
                            size_t neighbor_count,
                            uint32_t now_ms,
                            uint32_t valid_window_ms,
                            struct gradient_state *state)
{
    if (!state) {
        return;
    }

    state->leaf_type = LEAF_TYPE_NONE;
    state->gradient_level = GRADIENT_LEVEL_UNKNOWN;
    state->attached_backbone = 0;
    state->gradient_next_hop = 0;

    if (my_role != NODE_ROLE_LEAF || !neighbors || neighbor_count == 0) {
        return;
    }

    int8_t best_backbone_rssi = -127;
    uint16_t best_backbone_addr = 0;
    for (size_t i = 0; i < neighbor_count; i++) {
        const struct gradient_neighbor_info *n = &neighbors[i];
        if (n->addr == 0) {
            continue;
        }
        if ((now_ms - n->last_seen) > valid_window_ms) {
            continue;
        }
        if (n->role != NODE_ROLE_BACKBONE) {
            continue;
        }
        if (best_backbone_addr == 0 || n->rssi > best_backbone_rssi) {
            best_backbone_addr = n->addr;
            best_backbone_rssi = n->rssi;
        }
    }

    if (best_backbone_addr != 0) {
        state->leaf_type = LEAF_TYPE_BACKBONE_NEIGHBOR;
        state->gradient_level = 0;
        state->attached_backbone = best_backbone_addr;
        return;
    }

    state->leaf_type = LEAF_TYPE_GRADIENT;

    uint8_t best_level = UINT8_MAX;
    int8_t best_rssi = -127;
    uint16_t best_hop = 0;
    for (size_t i = 0; i < neighbor_count; i++) {
        const struct gradient_neighbor_info *n = &neighbors[i];
        if (n->addr == 0) {
            continue;
        }
        if ((now_ms - n->last_seen) > valid_window_ms) {
            continue;
        }
        if (n->role != NODE_ROLE_LEAF) {
            continue;
        }
        bool valid_seed = (n->leaf_type == LEAF_TYPE_BACKBONE_NEIGHBOR && n->gradient_level == 0);
        bool valid_gradient = (n->leaf_type == LEAF_TYPE_GRADIENT && n->gradient_level != GRADIENT_LEVEL_UNKNOWN);
        if (!valid_seed && !valid_gradient) {
            continue;
        }

        if (best_hop == 0 || n->gradient_level < best_level || (n->gradient_level == best_level && n->rssi > best_rssi)) {
            best_hop = n->addr;
            best_level = n->gradient_level;
            best_rssi = n->rssi;
        }
    }

    if (best_hop == 0 || best_level >= GRADIENT_LEVEL_UNKNOWN) {
        return;
    }

    state->gradient_next_hop = best_hop;
    state->gradient_level = (best_level >= (GRADIENT_LEVEL_UNKNOWN - 1)) ? GRADIENT_LEVEL_UNKNOWN : (uint8_t)(best_level + 1);
}

uint16_t gradient_pick_next_hop(uint16_t dsdv_next_hop,
                                node_role_t my_role,
                                const struct gradient_state *state)
{
    if (dsdv_next_hop != 0) {
        return dsdv_next_hop;
    }

    if (my_role != NODE_ROLE_LEAF || !state) {
        return 0;
    }

    if (state->leaf_type == LEAF_TYPE_BACKBONE_NEIGHBOR) {
        return state->attached_backbone;
    }
    if (state->leaf_type == LEAF_TYPE_GRADIENT) {
        return state->gradient_next_hop;
    }
    return 0;
}
```
